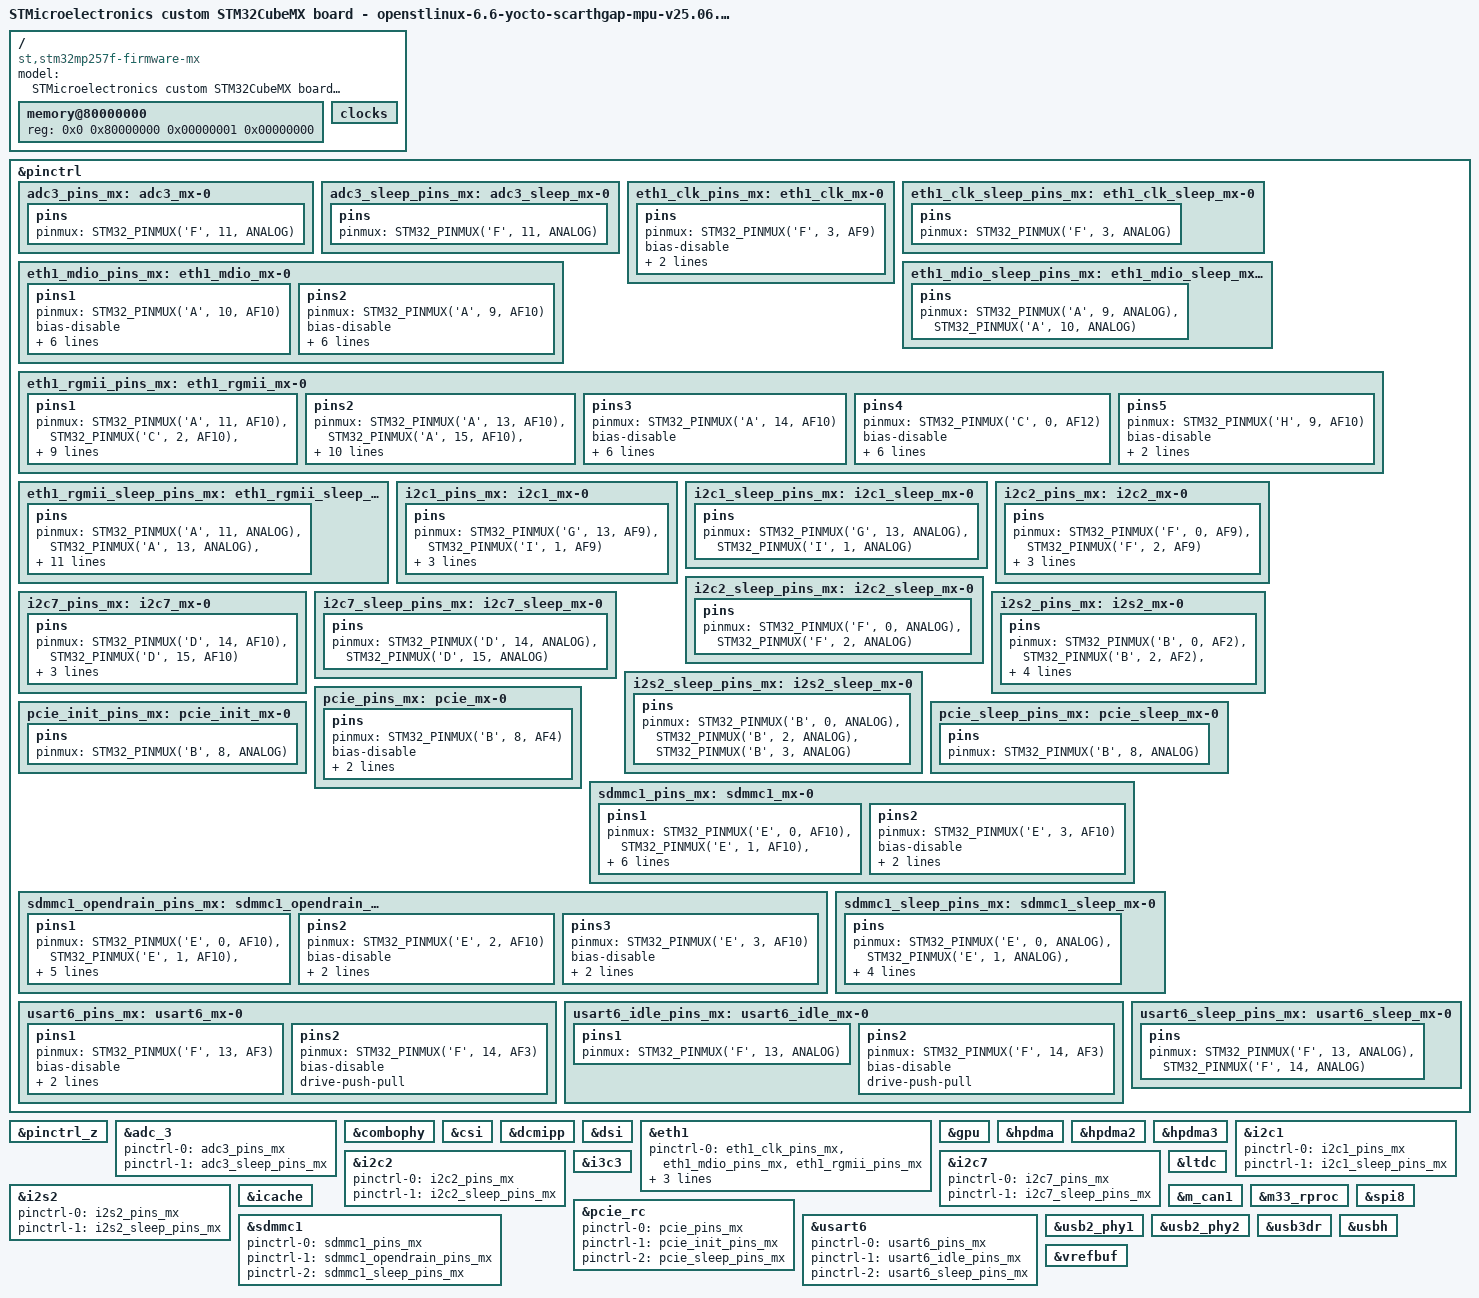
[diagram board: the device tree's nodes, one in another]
// SPDX-License-Identifier: (GPL-2.0-only OR BSD-3-Clause)
/*
 * Copyright (C) 2025, STMicroelectronics - All Rights Reserved
 * Author: STM32CubeMX code generation for STMicroelectronics.
 */

/* For more information on Device Tree configuration, please refer to
 * https://wiki.st.com/stm32mpu/wiki/Category:Device_tree_configuration
 */

/dts-v1/;

#include <dt-bindings/pinctrl/stm32-pinfunc.h>
#include "stm32mp257.dtsi"
#include "stm32mp25xf.dtsi"
#include "stm32mp257f-firmware-mx-resmem.dtsi"
#include "stm32mp25xxak-pinctrl.dtsi"

/* USER CODE BEGIN includes */
/* USER CODE END includes */

/ {
	model = "STMicroelectronics custom STM32CubeMX board - openstlinux-6.6-yocto-scarthgap-mpu-v25.06.11";
	compatible = "st,stm32mp257f-firmware-mx", "st,stm32mp257";

	memory@80000000 {
		device_type = "memory";
		reg = <0x0 0x80000000 0x00000001 0x00000000>;

		/* USER CODE BEGIN memory */
		/* USER CODE END memory */
	};

	/* USER CODE BEGIN root */
	/* USER CODE END root */

	clocks{

		/* USER CODE BEGIN clocks */
		/* USER CODE END clocks */
	};

}; /*root*/

&pinctrl {

	adc3_pins_mx: adc3_mx-0 {
		pins {
			pinmux = <STM32_PINMUX('F', 11, ANALOG)>; /* ADC3_INP6 */
		};
	};

	adc3_sleep_pins_mx: adc3_sleep_mx-0 {
		pins {
			pinmux = <STM32_PINMUX('F', 11, ANALOG)>; /* ADC3_INP6 */
		};
	};

	eth1_clk_pins_mx: eth1_clk_mx-0 {
		pins {
			pinmux = <STM32_PINMUX('F', 3, AF9)>; /* ETH1_CLK */
			bias-disable;
			drive-push-pull;
			slew-rate = <1>;
		};
	};

	eth1_clk_sleep_pins_mx: eth1_clk_sleep_mx-0 {
		pins {
			pinmux = <STM32_PINMUX('F', 3, ANALOG)>; /* ETH1_CLK */
		};
	};

	eth1_mdio_pins_mx: eth1_mdio_mx-0 {
		pins1 {
			pinmux = <STM32_PINMUX('A', 10, AF10)>; /* ETH1_MDIO */
			bias-disable;
			drive-push-pull;
			slew-rate = <0>;
			st,io-clk-edge = <0>;
			st,io-retime = <0>;
			st,io-delay-path = <0>;
			st,io-delay = <0>;
		};
		pins2 {
			pinmux = <STM32_PINMUX('A', 9, AF10)>; /* ETH1_MDC */
			bias-disable;
			drive-push-pull;
			slew-rate = <2>;
			st,io-clk-edge = <0>;
			st,io-retime = <0>;
			st,io-delay-path = <0>;
			st,io-delay = <0>;
		};
	};

	eth1_mdio_sleep_pins_mx: eth1_mdio_sleep_mx-0 {
		pins {
			pinmux = <STM32_PINMUX('A', 9, ANALOG)>, /* ETH1_MDC */
					 <STM32_PINMUX('A', 10, ANALOG)>; /* ETH1_MDIO */
		};
	};

	eth1_rgmii_pins_mx: eth1_rgmii_mx-0 {
		pins1 {
			pinmux = <STM32_PINMUX('A', 11, AF10)>, /* ETH1_RGMII_RX_CTL */
					 <STM32_PINMUX('C', 2, AF10)>, /* ETH1_RGMII_RXD1 */
					 <STM32_PINMUX('F', 1, AF10)>, /* ETH1_RGMII_RXD0 */
					 <STM32_PINMUX('H', 12, AF10)>, /* ETH1_RGMII_RXD2 */
					 <STM32_PINMUX('H', 13, AF10)>; /* ETH1_RGMII_RXD3 */
			bias-disable;
			drive-push-pull;
			st,io-clk-edge = <1>;
			st,io-retime = <1>;
			st,io-delay-path = <0>;
			st,io-delay = <0>;
		};
		pins2 {
			pinmux = <STM32_PINMUX('A', 13, AF10)>, /* ETH1_RGMII_TX_CTL */
					 <STM32_PINMUX('A', 15, AF10)>, /* ETH1_RGMII_TXD0 */
					 <STM32_PINMUX('C', 1, AF10)>, /* ETH1_RGMII_TXD1 */
					 <STM32_PINMUX('H', 10, AF10)>, /* ETH1_RGMII_TXD2 */
					 <STM32_PINMUX('H', 11, AF10)>; /* ETH1_RGMII_TXD3 */
			bias-disable;
			drive-push-pull;
			slew-rate = <2>;
			st,io-clk-edge = <1>;
			st,io-retime = <1>;
			st,io-delay-path = <0>;
			st,io-delay = <0>;
		};
		pins3 {
			pinmux = <STM32_PINMUX('A', 14, AF10)>; /* ETH1_RGMII_RX_CLK */
			bias-disable;
			drive-push-pull;
			slew-rate = <0>;
			st,io-clk-edge = <0>;
			st,io-retime = <0>;
			st,io-delay-path = <0>;
			st,io-delay = <0>;
		};
		pins4 {
			pinmux = <STM32_PINMUX('C', 0, AF12)>; /* ETH1_RGMII_GTX_CLK */
			bias-disable;
			drive-push-pull;
			slew-rate = <1>;
			st,io-clk-edge = <0>;
			st,io-retime = <0>;
			st,io-delay-path = <0>;
			st,io-delay = <0>;
		};
		pins5 {
			pinmux = <STM32_PINMUX('H', 9, AF10)>; /* ETH1_RGMII_CLK125 */
			bias-disable;
			drive-push-pull;
			slew-rate = <2>;
		};
	};

	eth1_rgmii_sleep_pins_mx: eth1_rgmii_sleep_mx-0 {
		pins {
			pinmux = <STM32_PINMUX('A', 11, ANALOG)>, /* ETH1_RGMII_RX_CTL */
					 <STM32_PINMUX('A', 13, ANALOG)>, /* ETH1_RGMII_TX_CTL */
					 <STM32_PINMUX('A', 14, ANALOG)>, /* ETH1_RGMII_RX_CLK */
					 <STM32_PINMUX('A', 15, ANALOG)>, /* ETH1_RGMII_TXD0 */
					 <STM32_PINMUX('C', 0, ANALOG)>, /* ETH1_RGMII_GTX_CLK */
					 <STM32_PINMUX('C', 1, ANALOG)>, /* ETH1_RGMII_TXD1 */
					 <STM32_PINMUX('C', 2, ANALOG)>, /* ETH1_RGMII_RXD1 */
					 <STM32_PINMUX('F', 1, ANALOG)>, /* ETH1_RGMII_RXD0 */
					 <STM32_PINMUX('H', 9, ANALOG)>, /* ETH1_RGMII_CLK125 */
					 <STM32_PINMUX('H', 10, ANALOG)>, /* ETH1_RGMII_TXD2 */
					 <STM32_PINMUX('H', 11, ANALOG)>, /* ETH1_RGMII_TXD3 */
					 <STM32_PINMUX('H', 12, ANALOG)>, /* ETH1_RGMII_RXD2 */
					 <STM32_PINMUX('H', 13, ANALOG)>; /* ETH1_RGMII_RXD3 */
		};
	};

	i2c1_pins_mx: i2c1_mx-0 {
		pins {
			pinmux = <STM32_PINMUX('G', 13, AF9)>, /* I2C1_SCL */
					 <STM32_PINMUX('I', 1, AF9)>; /* I2C1_SDA */
			bias-disable;
			drive-open-drain;
			slew-rate = <0>;
		};
	};

	i2c1_sleep_pins_mx: i2c1_sleep_mx-0 {
		pins {
			pinmux = <STM32_PINMUX('G', 13, ANALOG)>, /* I2C1_SCL */
					 <STM32_PINMUX('I', 1, ANALOG)>; /* I2C1_SDA */
		};
	};

	i2c2_pins_mx: i2c2_mx-0 {
		pins {
			pinmux = <STM32_PINMUX('F', 0, AF9)>, /* I2C2_SDA */
					 <STM32_PINMUX('F', 2, AF9)>; /* I2C2_SCL */
			bias-disable;
			drive-open-drain;
			slew-rate = <0>;
		};
	};

	i2c2_sleep_pins_mx: i2c2_sleep_mx-0 {
		pins {
			pinmux = <STM32_PINMUX('F', 0, ANALOG)>, /* I2C2_SDA */
					 <STM32_PINMUX('F', 2, ANALOG)>; /* I2C2_SCL */
		};
	};

	i2c7_pins_mx: i2c7_mx-0 {
		pins {
			pinmux = <STM32_PINMUX('D', 14, AF10)>, /* I2C7_SDA */
					 <STM32_PINMUX('D', 15, AF10)>; /* I2C7_SCL */
			bias-disable;
			drive-open-drain;
			slew-rate = <0>;
		};
	};

	i2c7_sleep_pins_mx: i2c7_sleep_mx-0 {
		pins {
			pinmux = <STM32_PINMUX('D', 14, ANALOG)>, /* I2C7_SDA */
					 <STM32_PINMUX('D', 15, ANALOG)>; /* I2C7_SCL */
		};
	};

	i2s2_pins_mx: i2s2_mx-0 {
		pins {
			pinmux = <STM32_PINMUX('B', 0, AF2)>, /* I2S2_CK */
					 <STM32_PINMUX('B', 2, AF2)>, /* I2S2_SDO */
					 <STM32_PINMUX('B', 3, AF2)>; /* I2S2_WS */
			bias-disable;
			drive-push-pull;
			slew-rate = <0>;
		};
	};

	i2s2_sleep_pins_mx: i2s2_sleep_mx-0 {
		pins {
			pinmux = <STM32_PINMUX('B', 0, ANALOG)>, /* I2S2_CK */
					 <STM32_PINMUX('B', 2, ANALOG)>, /* I2S2_SDO */
					 <STM32_PINMUX('B', 3, ANALOG)>; /* I2S2_WS */
		};
	};

	pcie_pins_mx: pcie_mx-0 {
		pins {
			pinmux = <STM32_PINMUX('B', 8, AF4)>; /* PCIE_CLKREQN */
			bias-disable;
			drive-push-pull;
			slew-rate = <0>;
		};
	};

	pcie_init_pins_mx: pcie_init_mx-0 {
		pins {
			pinmux = <STM32_PINMUX('B', 8, ANALOG)>; /* PCIE_CLKREQN */
		};
	};

	pcie_sleep_pins_mx: pcie_sleep_mx-0 {
		pins {
			pinmux = <STM32_PINMUX('B', 8, ANALOG)>; /* PCIE_CLKREQN */
		};
	};

	sdmmc1_pins_mx: sdmmc1_mx-0 {
		pins1 {
			pinmux = <STM32_PINMUX('E', 0, AF10)>, /* SDMMC1_D2 */
					 <STM32_PINMUX('E', 1, AF10)>, /* SDMMC1_D3 */
					 <STM32_PINMUX('E', 2, AF10)>, /* SDMMC1_CMD */
					 <STM32_PINMUX('E', 4, AF10)>, /* SDMMC1_D0 */
					 <STM32_PINMUX('E', 5, AF10)>; /* SDMMC1_D1 */
			bias-disable;
			drive-push-pull;
			slew-rate = <1>;
		};
		pins2 {
			pinmux = <STM32_PINMUX('E', 3, AF10)>; /* SDMMC1_CK */
			bias-disable;
			drive-push-pull;
			slew-rate = <3>;
		};
	};

	sdmmc1_opendrain_pins_mx: sdmmc1_opendrain_mx-0 {
		pins1 {
			pinmux = <STM32_PINMUX('E', 0, AF10)>, /* SDMMC1_D2 */
					 <STM32_PINMUX('E', 1, AF10)>, /* SDMMC1_D3 */
					 <STM32_PINMUX('E', 4, AF10)>, /* SDMMC1_D0 */
					 <STM32_PINMUX('E', 5, AF10)>; /* SDMMC1_D1 */
			bias-disable;
			drive-push-pull;
			slew-rate = <1>;
		};
		pins2 {
			pinmux = <STM32_PINMUX('E', 2, AF10)>; /* SDMMC1_CMD */
			bias-disable;
			drive-open-drain;
			slew-rate = <1>;
		};
		pins3 {
			pinmux = <STM32_PINMUX('E', 3, AF10)>; /* SDMMC1_CK */
			bias-disable;
			drive-push-pull;
			slew-rate = <3>;
		};
	};

	sdmmc1_sleep_pins_mx: sdmmc1_sleep_mx-0 {
		pins {
			pinmux = <STM32_PINMUX('E', 0, ANALOG)>, /* SDMMC1_D2 */
					 <STM32_PINMUX('E', 1, ANALOG)>, /* SDMMC1_D3 */
					 <STM32_PINMUX('E', 2, ANALOG)>, /* SDMMC1_CMD */
					 <STM32_PINMUX('E', 3, ANALOG)>, /* SDMMC1_CK */
					 <STM32_PINMUX('E', 4, ANALOG)>, /* SDMMC1_D0 */
					 <STM32_PINMUX('E', 5, ANALOG)>; /* SDMMC1_D1 */
		};
	};

	usart6_pins_mx: usart6_mx-0 {
		pins1 {
			pinmux = <STM32_PINMUX('F', 13, AF3)>; /* USART6_TX */
			bias-disable;
			drive-push-pull;
			slew-rate = <0>;
		};
		pins2 {
			pinmux = <STM32_PINMUX('F', 14, AF3)>; /* USART6_RX */
			bias-disable;
			drive-push-pull;
		};
	};

	usart6_idle_pins_mx: usart6_idle_mx-0 {
		pins1 {
			pinmux = <STM32_PINMUX('F', 13, ANALOG)>; /* USART6_TX */
		};
		pins2 {
			pinmux = <STM32_PINMUX('F', 14, AF3)>; /* USART6_RX */
			bias-disable;
			drive-push-pull;
		};
	};

	usart6_sleep_pins_mx: usart6_sleep_mx-0 {
		pins {
			pinmux = <STM32_PINMUX('F', 13, ANALOG)>, /* USART6_TX */
					 <STM32_PINMUX('F', 14, ANALOG)>; /* USART6_RX */
		};
	};

	/* USER CODE BEGIN pinctrl */
	/* USER CODE END pinctrl */
};

&pinctrl_z {

	/* USER CODE BEGIN pinctrl_z */
	/* USER CODE END pinctrl_z */
};

&adc_3 {
	pinctrl-names = "default", "sleep";
	pinctrl-0 = <&adc3_pins_mx>;
	pinctrl-1 = <&adc3_sleep_pins_mx>;
	status = "okay";

	/* USER CODE BEGIN adc_3 */
	/* USER CODE END adc_3 */
};

&combophy {
	status = "okay";

	/* USER CODE BEGIN combophy */
	/* USER CODE END combophy */
};

&csi {
	status = "okay";

	/* USER CODE BEGIN csi */
	/* USER CODE END csi */
};

&dcmipp {
	status = "okay";

	/* USER CODE BEGIN dcmipp */
	/* USER CODE END dcmipp */
};

&dsi {
	status = "okay";

	/* USER CODE BEGIN dsi */
	/* USER CODE END dsi */
};

&eth1 {
	pinctrl-names = "default", "sleep";
	pinctrl-0 = <&eth1_clk_pins_mx>, <&eth1_mdio_pins_mx>, <&eth1_rgmii_pins_mx>;
	pinctrl-1 = <&eth1_clk_sleep_pins_mx>, <&eth1_mdio_sleep_pins_mx>, <&eth1_rgmii_sleep_pins_mx>;
	status = "okay";

	/* USER CODE BEGIN eth1 */
	/* USER CODE END eth1 */
};

&gpu {
	status = "okay";

	/* USER CODE BEGIN gpu */
	/* USER CODE END gpu */
};

&hpdma {
	status = "okay";

	/* USER CODE BEGIN hpdma */
	/* USER CODE END hpdma */
};

&hpdma2 {
	status = "okay";

	/* USER CODE BEGIN hpdma2 */
	/* USER CODE END hpdma2 */
};

&hpdma3 {
	status = "okay";

	/* USER CODE BEGIN hpdma3 */
	/* USER CODE END hpdma3 */
};

&i2c1 {
	pinctrl-names = "default", "sleep";
	pinctrl-0 = <&i2c1_pins_mx>;
	pinctrl-1 = <&i2c1_sleep_pins_mx>;
	status = "okay";

	/* USER CODE BEGIN i2c1 */
	/* USER CODE END i2c1 */
};

&i2c2 {
	pinctrl-names = "default", "sleep";
	pinctrl-0 = <&i2c2_pins_mx>;
	pinctrl-1 = <&i2c2_sleep_pins_mx>;
	status = "okay";

	/* USER CODE BEGIN i2c2 */
	/* USER CODE END i2c2 */
};

&i2c7 {
	pinctrl-names = "default", "sleep";
	pinctrl-0 = <&i2c7_pins_mx>;
	pinctrl-1 = <&i2c7_sleep_pins_mx>;
	status = "okay";

	/* USER CODE BEGIN i2c7 */
	/* USER CODE END i2c7 */
};

&i2s2 {
	pinctrl-names = "default", "sleep";
	pinctrl-0 = <&i2s2_pins_mx>;
	pinctrl-1 = <&i2s2_sleep_pins_mx>;
	status = "okay";

	/* USER CODE BEGIN i2s2 */
	/* USER CODE END i2s2 */
};

&i3c3 {
	status = "okay";

	/* USER CODE BEGIN i3c3 */
	/* USER CODE END i3c3 */
};

&icache {
	status = "okay";

	/* USER CODE BEGIN icache */
	/* USER CODE END icache */
};

&ltdc {
	status = "okay";

	/* USER CODE BEGIN ltdc */
	/* USER CODE END ltdc */
};

&m_can1 {
	status = "okay";

	/* USER CODE BEGIN m_can1 */
	/* USER CODE END m_can1 */
};

&m33_rproc {
	status = "okay";

	/* USER CODE BEGIN m33_rproc */
	/* USER CODE END m33_rproc */
};

&pcie_rc {
	pinctrl-names = "default", "init", "sleep";
	pinctrl-0 = <&pcie_pins_mx>;
	pinctrl-1 = <&pcie_init_pins_mx>;
	pinctrl-2 = <&pcie_sleep_pins_mx>;
	status = "okay";

	/* USER CODE BEGIN pcie_rc */
	/* USER CODE END pcie_rc */
};

&sdmmc1 {
	pinctrl-names = "default", "opendrain", "sleep";
	pinctrl-0 = <&sdmmc1_pins_mx>;
	pinctrl-1 = <&sdmmc1_opendrain_pins_mx>;
	pinctrl-2 = <&sdmmc1_sleep_pins_mx>;
	status = "okay";

	/* USER CODE BEGIN sdmmc1 */
	/* USER CODE END sdmmc1 */
};

&spi8 {
	status = "okay";

	/* USER CODE BEGIN spi8 */
	/* USER CODE END spi8 */
};

&usart6 {
	pinctrl-names = "default", "idle", "sleep";
	pinctrl-0 = <&usart6_pins_mx>;
	pinctrl-1 = <&usart6_idle_pins_mx>;
	pinctrl-2 = <&usart6_sleep_pins_mx>;
	status = "okay";

	/* USER CODE BEGIN usart6 */
	/* USER CODE END usart6 */
};

&usb2_phy1 {
	status = "okay";

	/* USER CODE BEGIN usb2_phy1 */
	/* USER CODE END usb2_phy1 */
};

&usb2_phy2 {
	status = "okay";

	/* USER CODE BEGIN usb2_phy2 */
	/* USER CODE END usb2_phy2 */
};

&usb3dr {
	status = "okay";

	/* USER CODE BEGIN usb3dr */
	/* USER CODE END usb3dr */
};

&usbh {
	status = "okay";

	/* USER CODE BEGIN usbh */
	/* USER CODE END usbh */
};

&vrefbuf {
	status = "okay";

	/* USER CODE BEGIN vrefbuf */
	/* USER CODE END vrefbuf */
};

/* USER CODE BEGIN addons */
/* USER CODE END addons */

